# AS32x601 register map
File version: 1.0
CPU: RISC-V, little endian
Registers are 32-bit, read-write, reset 0x0 unless marked. A register's access mark holds for its fields unless they carry their own. Offsets are from the block's base; [hi:lo] are bit positions; {n}, {i} and the like mark numbered series; 'fields as' and 'values as' point back to an identical list.

## CLINT — Core-Local Interruptor
Base 0x30010000
0x00 SOFTICR — Soft interrupt control register
  [0] SOFT — Writing 1 will trigger a soft interrupt
0x4000 CMPLR wo — Compare registers with lower 32 bits
  [31:0] CMP — Comparator value that generates a timer interrupt when the real-time counter is equal to this value [31:0]
0x4004 CMPHR wo — Compare registers with 32 higher bits
  fields as CMPLR
0xBFF8 RDTIMELR ro — Real-time counter low 32 bit register
  [31:0] DRTIME — Real-time counter low 32 bit [31:0]
0xBFFC RDTIMEHR ro — Real-time counter high 32 bit register
  [31:0] DRTIME — Real-time counter high 32 bit [31:0]

## PLIC — Core-Local Interruptor
Base 0x30020000
0x00 ID — Interrupt source ID numer registers
  [7:0] ID — Interrupt ID number
{0x4+4i} PRIORITY[{i}] (i=0..63) — Interrupt source priority register {i}
  [7:0] PRIORITY — Interrupt source priority
0x104 EN0 — Interrupt source enable registe 0
  [31:0] EN — Interrupt enable from 32 to 1
0x108 EN1 — Interrupt source enable registe 1
  [31:0] EN — Interrupt enable from 64 to 33

## FCU — Fault Collection Unit
Base 0x30004000
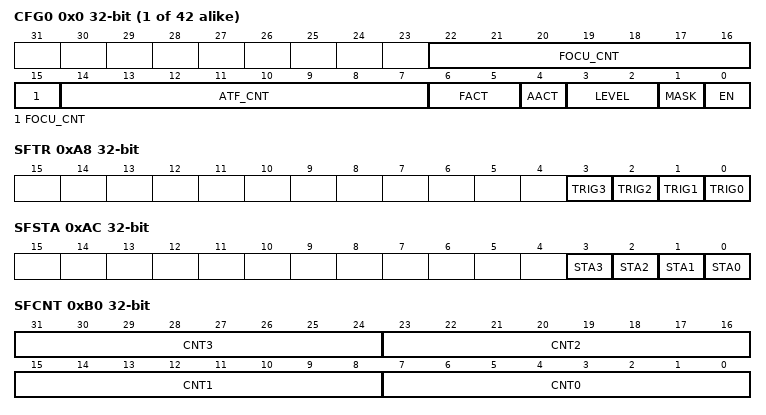
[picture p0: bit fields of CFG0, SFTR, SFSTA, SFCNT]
{0x0+4i} CFG{i} (i=0..41) — FCU Config register {i}
  [22:15] FOCU_CNT — FCU channel fault to reset count [7:0]
  [14:7] ATF_CNT — FCU channel alarm to fault count [7:0]
  [6:5] FACT — FCU channel fault action [1:0]
  [4] AACT — FCU channel alarm action
  [3:2] LEVEL — FCU channel fault level [1:0]
  [1] MASK — FCU channel mask config
  [0] EN — FCU channel enable
0xA8 SFTR — Software Fault Trigger register
  [n] TRIG{n} (n=0..3) — Software fault channel {n} trigger bit
0xAC SFSTA ro — Software Fault Status register
  [n] STA{n} (n=0..3) — Software fault channel {n} status bit
0xB0 SFCNT — Software Fault Count register
  [8n+7:8n] CNT{n} (n=0..3) — Software fault channel {n} count [7:0]
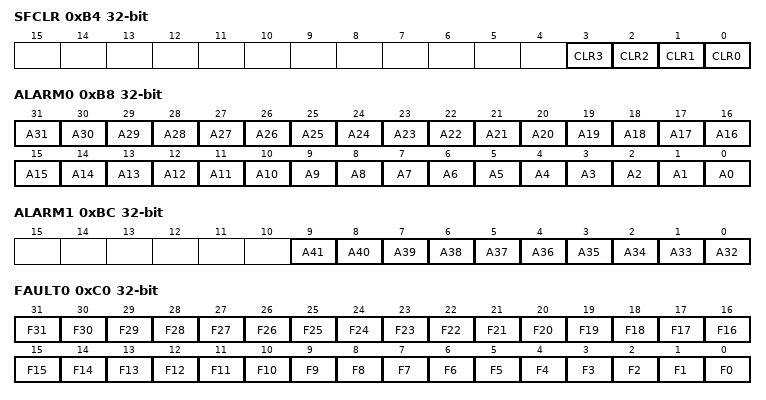
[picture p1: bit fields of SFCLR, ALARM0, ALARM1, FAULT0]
0xB4 SFCLR — Software Fault Clear register
  [n] CLR{n} (n=0..3) — Software fault channel {n} clear bit
0xB8 ALARM0 ro — Fault Alert register 0
  [n] A{n} (n=0..31) — FCU Channel {n} alarm bit
0xBC ALARM1 ro — Fault Alert register 1
  [n-32] A{n} (n=32..41) — FCU Channel {n} alarm bit
0xC0 FAULT0 ro — Fault Source register 0
  [n] F{n} (n=0..31) — FCU Channel {n} fault bit
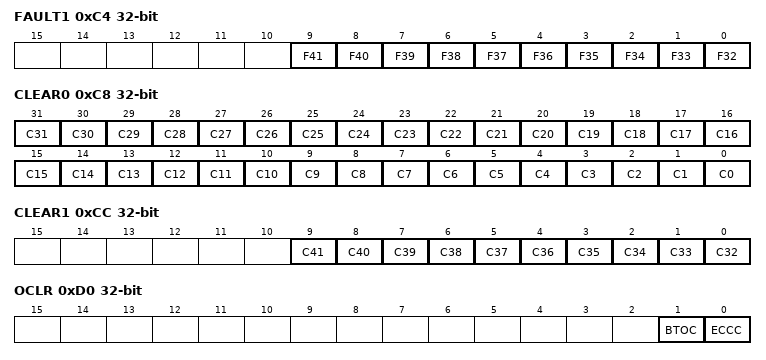
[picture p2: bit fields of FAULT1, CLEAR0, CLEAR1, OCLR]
0xC4 FAULT1 ro — Fault Source register 1
  [n-32] F{n} (n=32..41) — FCU Channel {n} fault bit
0xC8 CLEAR0 — Fault/Alarm Clear register 0
  [n] C{n} (n=0..31) — FCU Channel {n} clear bit
0xCC CLEAR1 — Fault/Alarm Clear register 1
  [n-32] C{n} (n=32..41) — FCU Channel {n} clear bit
0xD0 OCLR — Bus Timeout/ECC Clear register
  [1] BTOC — Bus timeout count fault clear bit
  [0] ECCC — ECC controller fault clear bit

## MPU_IBUS — MPU I-Port Bus Protection Unit
Base 0x30000000
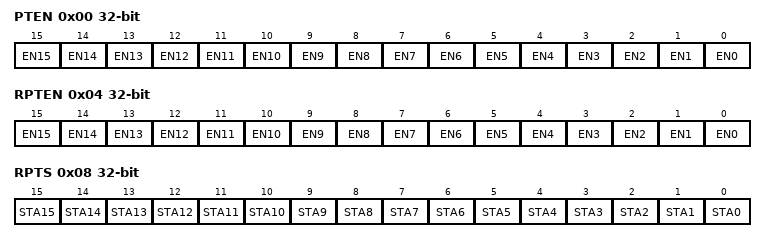
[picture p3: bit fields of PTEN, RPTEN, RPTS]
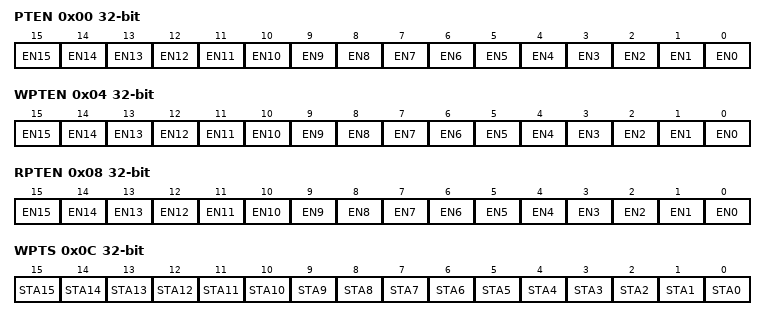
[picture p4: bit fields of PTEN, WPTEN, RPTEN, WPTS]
0x00 PTEN — MPU Protection Enable register
  [n] EN{n} (n=0..15) — Enable MPU Channel {n}
0x04 RPTEN — MPU Read Protection Enable register
  [n] EN{n} (n=0..15) — Read Protection Enable signal {n}
0x08 RPTS — MPU Read Protection Status register
  [n] STA{n} (n=0..15) — Read Protection Status {n}
{0xC+8i} CH{i}_SADDR (i=0..15) — Channel {i} Start Address register
  [31:0] ADDR — Start address {i}
{0x10+8i} CH{i}_EADDR (i=0..15) — Channel {i} End Address register
  [31:0] ADDR — End address {i}

## MPU_DBUS — MPU D-Port Bus Protection Unit
Base 0x30000400
Same registers: MPU_PBUS 0x30000800
0x00 PTEN — MPU Protection Enable register
  [n] EN{n} (n=0..15) — Enable MPU Channel {n}
0x04 WPTEN — MPU Write Protection Enable register
  [n] EN{n} (n=0..15) — Write Protection Enable signal {n}
0x08 RPTEN — MPU Read Protection Enable register
  [n] EN{n} (n=0..15) — Read Protection Enable signal {n}
0x0C WPTS — MPU Write Protection Status register
  [n] STA{n} (n=0..15) — Write Protection Status {n}
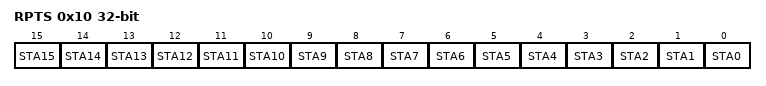
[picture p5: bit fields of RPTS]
0x10 RPTS — MPU Read Protection Status register
  [n] STA{n} (n=0..15) — Read Protection Status {n}
{0x14+8i} CH{i}_SADDR (i=0..15) — Channel {i} Start Address Register
  [31:0] ADDR — Start address {i}
{0x18+8i} CH{i}_EADDR (i=0..15) — Channel {i} End Address Register
  [31:0] ADDR — End address {i}

## MPU_DMA0 — MPU DMA0-Port Protection Unit
Base 0x30000C00
Same registers: MPU_DMA1 0x30001000
Registers as MPU_DBUS, without CH{n}_SADDR (n=8..15), CH{n}_EADDR (n=8..15); these are added or differ:
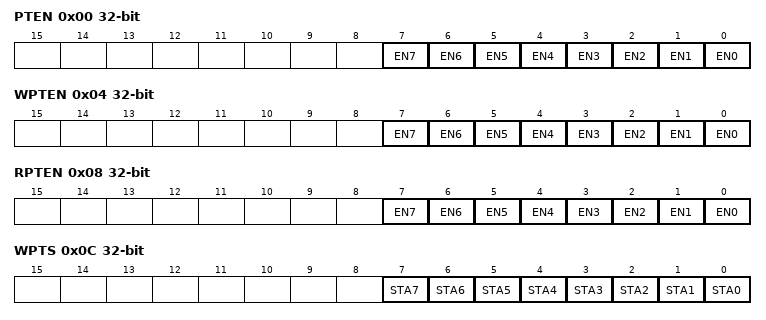
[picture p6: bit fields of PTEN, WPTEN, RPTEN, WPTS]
0x00 PTEN — MPU Protection Enable register
  [n] EN{n} (n=0..7) — Enable MPU Channel {n}
0x04 WPTEN — MPU Write Protection Enable register
  [n] EN{n} (n=0..7) — Write Protection Enable signal {n}
0x08 RPTEN — MPU Read Protection Enable register
  [n] EN{n} (n=0..7) — Read Protection Enable signal {n}
0x0C WPTS — MPU Write Protection Status register
  [n] STA{n} (n=0..7) — Write Protection Status {n}
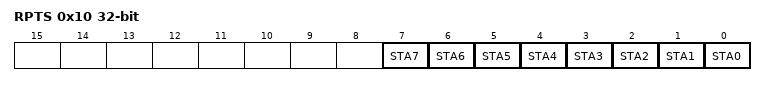
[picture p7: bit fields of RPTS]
0x10 RPTS — MPU Read Protection Status register
  [n] STA{n} (n=0..7) — Read Protection Status {n}
